# ATSAM4SP32A register map
Vendor: Atmel; File version: 0
CPU: CM4 r0p1, selectable endian, no MPU, no FPU, 0x4 interrupt priority bits, 0x0 interrupts
Registers are 32-bit, read-write, reset 0x0 unless marked. A register's access mark holds for its fields unless they carry their own. Offsets are from the block's base; [hi:lo] are bit positions; {n}, {i} and the like mark numbered series; 'fields as' and 'values as' point back to an identical list.

## CHIPID — Chip Identifier
Base 0x400E0740; register names take the prefix CHIPID_
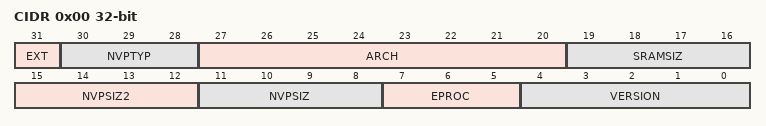
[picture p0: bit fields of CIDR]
0x00 CIDR ro reset not defined — Chip ID Register
  [31] EXT — Extension Flag
  [30:28] NVPTYP — Nonvolatile Program Memory Type
    0=ROM; 1=ROMLESS (ROMless or on-chip Flash); 2=FLASH (Embedded Flash Memory); 3=ROM_FLASH (ROM and Embedded Flash MemoryNVPSIZ is ROM size NVPSIZ2 is Flash size); 4=SRAM (SRAM emulating ROM)
  [27:20] ARCH — Architecture Identifier
    25=AT91SAM9xx Series; 41=AT91SAM9XExx Series; 52=AT91x34 Series; 55=CAP7 (CAP7 Series); 57=CAP9 (CAP9 Series); 59=CAP11 (CAP11 Series); 60=CM4P (CM4P Series); 64=AT91x40 Series; 66=AT91x42 Series; 85=AT91x55 Series; 96=AT91SAM7Axx Series; 97=AT91SAM7AQxx Series; 99=AT91x63 Series; 100=SAM4CxxC (SAM4CxC Series (100-pin version)); 101=SAM4MxxC Series (100-pin version); 112=AT91SAM7Sxx Series; 113=AT91SAM7XCxx Series; 114=AT91SAM7SExx Series; 115=AT91SAM7Lxx Series; 117=AT91SAM7Xxx Series; 118=AT91SAM7SLxx Series; 128=SAM3UxC Series (100-pin version); 129=SAM3UxE Series (144-pin version); 131=SAM3AxC Series (100-pin version); 132=SAM3XxC Series (100-pin version); 133=SAM3XxE Series (144-pin version); 134=SAM3XxG Series (208/217-pin version); 136=SAM3SxASeries (48-pin version); 136=SAM4SxA Series (48-pin version); 137=SAM3SxB Series (64-pin version); 137=SAM4SxB Series (64-pin version); 138=SAM3SxC Series (100-pin version); 138=SAM4SxC Series (100-pin version); 146=AT91x92 Series; 147=SAM3NxA Series (48-pin version); 148=SAM3NxB Series (64-pin version); 149=SAM3NxC Series (100-pin version); 153=SAM3SDxB Series (64-pin version); 154=SAM3SDxC Series (100-pin version); 165=SAM5A; 176=SAM4LxA Series (48-pin version); 177=SAM4LxB Series (64-pin version); 178=SAM4LxC Series (100-pin version); 240=AT75Cxx Series
  [19:16] SRAMSIZ — Internal SRAM Size
    0=48K (48 Kbytes); 1=192K (192 Kbytes); 2=2K (2 Kbytes); 3=6K (6 Kbytes); 4=24K (24 Kbytes); 5=4K (4 Kbytes); 6=80K (80 Kbytes); 7=160K (160 Kbytes); 8=8K (8 Kbytes); 9=16K (16 Kbytes); 10=32K (32 Kbytes); 11=64K (64 Kbytes); 12=128K (128 Kbytes); 13=256K (256 Kbytes); 14=96K (96 Kbytes); 15=512K (512 Kbytes)
  [15:12] NVPSIZ2 — Second Nonvolatile Program Memory Size
    0=NONE; 1=8K (8 Kbytes); 2=16K (16 Kbytes); 3=32K (32 Kbytes); 5=64K (64 Kbytes); 7=128K (128 Kbytes); 9=256K (256 Kbytes); 10=512K (512 Kbytes); 12=1024K (1024 Kbytes); 14=2048K (2048 Kbytes)
  [11:8] NVPSIZ — Nonvolatile Program Memory Size
    values as NVPSIZ2
  [7:5] EPROC — Embedded Processor
    1=ARM946ES; 2=ARM7TDMI; 3=CM3 (Cortex-M3); 4=ARM920T; 5=ARM926EJS; 6=CA5 (Cortex-A5); 7=CM4 (Cortex-M4)
  [4:0] VERSION — Version of the Device
0x04 EXID ro reset not defined — Chip ID Extension Register
  [31:0] EXID — Chip ID Extension

## EFC0 — Embedded Flash Controller 0
Base 0x400E0A00; register names take the prefix EFC0_
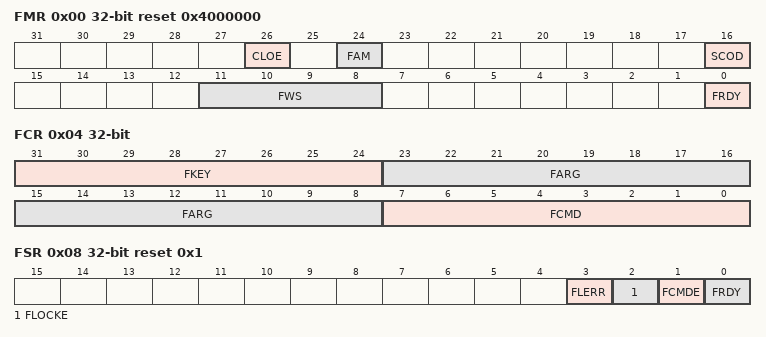
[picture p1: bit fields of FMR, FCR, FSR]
0x00 FMR reset 0x4000000 — EEFC Flash Mode Register
  [26] CLOE — Code Loops Optimization Enable
  [24] FAM — Flash Access Mode
  [16] SCOD — Sequential Code Optimization Disable
  [11:8] FWS — Flash Wait State
  [0] FRDY — Ready Interrupt Enable
0x04 FCR wo reset not defined — EEFC Flash Command Register
  [31:24] FKEY — Flash Writing Protection Key
    90=PASSWD (The 0x5A value enables the command defined by the bits of the register. If the field is written with a different value, the write is not performed and no action is started.)
  [23:8] FARG — Flash Command Argument
  [7:0] FCMD — Flash Command
    0=GETD (Get Flash Descriptor); 1=WP (Write page); 2=WPL (Write page and lock); 3=EWP (Erase page and write page); 4=EWPL (Erase page and write page then lock); 5=EA (Erase all); 7=EPA (Erase Pages); 8=SLB (Set Lock Bit); 9=CLB (Clear Lock Bit); 10=GLB (Get Lock Bit); 11=SGPB (Set GPNVM Bit); 12=CGPB (Clear GPNVM Bit); 13=GGPB (Get GPNVM Bit); 14=STUI (Start Read Unique Identifier); 15=SPUI (Stop Read Unique Identifier); 16=GCALB (Get CALIB Bit); 17=ES (Erase Sector); 18=WUS (Write User Signature); 19=EUS (Erase User Signature); 20=STUS (Start Read User Signature); 21=SPUS (Stop Read User Signature)
0x08 FSR ro reset 0x1 — EEFC Flash Status Register
  [3] FLERR — Flash Error Status
  [2] FLOCKE — Flash Lock Error Status
  [1] FCMDE — Flash Command Error Status
  [0] FRDY — Flash Ready Status
0x0C FRR ro — EEFC Flash Result Register
  [31:0] FVALUE — Flash Result Value

## EFC1 — Embedded Flash Controller 1
Base 0x400E0C00; register names take the prefix EFC1_
Registers as EFC0.

## RSTC — Reset Controller
Base 0x400E1400; register names take the prefix RSTC_
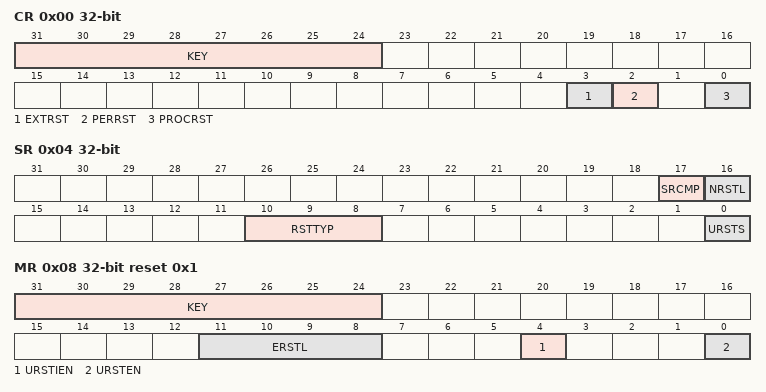
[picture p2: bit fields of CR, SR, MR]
0x00 CR wo reset not defined — Control Register
  [31:24] KEY — System Reset Key
  [3] EXTRST — External Reset
  [2] PERRST — Peripheral Reset
  [0] PROCRST — Processor Reset
0x04 SR ro — Status Register
  [17] SRCMP — Software Reset Command in Progress
  [16] NRSTL — NRST Pin Level
  [10:8] RSTTYP — Reset Type
  [0] URSTS — User Reset Status
0x08 MR reset 0x1 — Mode Register
  [31:24] KEY — Password
  [11:8] ERSTL — External Reset Length
  [4] URSTIEN — User Reset Interrupt Enable
  [0] URSTEN — User Reset Enable

## RTT — Real-time Timer
Base 0x400E1430; register names take the prefix RTT_
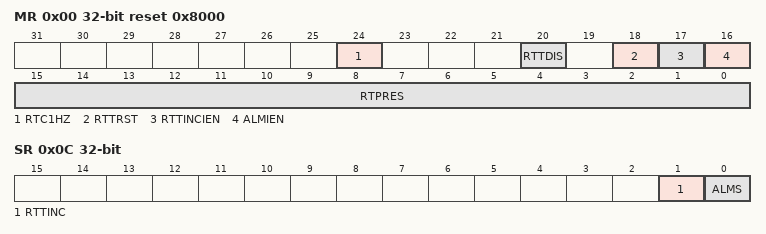
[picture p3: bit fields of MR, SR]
0x00 MR reset 0x8000 — Mode Register
  [24] RTC1HZ — Real-Time Clock 1Hz Clock Selection
  [20] RTTDIS — Real-time Timer Disable
  [18] RTTRST — Real-time Timer Restart
  [17] RTTINCIEN — Real-time Timer Increment Interrupt Enable
  [16] ALMIEN — Alarm Interrupt Enable
  [15:0] RTPRES — Real-time Timer Prescaler Value
0x04 AR reset 0xFFFFFFFF — Alarm Register
  [31:0] ALMV — Alarm Value
0x08 VR ro — Value Register
  [31:0] CRTV — Current Real-time Value
0x0C SR ro — Status Register
  [1] RTTINC — Real-time Timer Increment
  [0] ALMS — Real-time Alarm Status

## WDT — Watchdog Timer
Base 0x400E1450; register names take the prefix WDT_
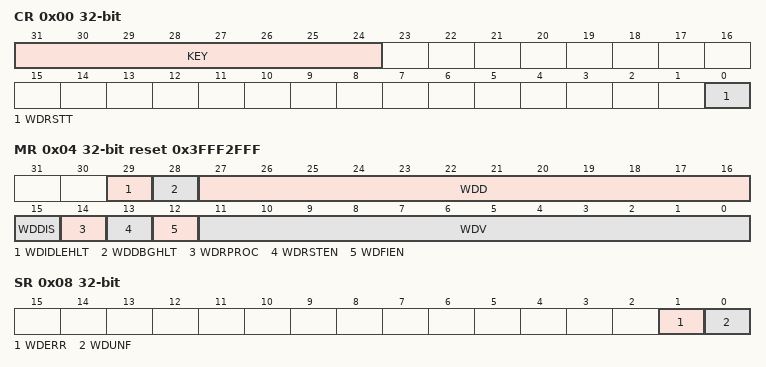
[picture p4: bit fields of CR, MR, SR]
0x00 CR wo reset not defined — Control Register
  [31:24] KEY — Password
  [0] WDRSTT — Watchdog Restart
0x04 MR reset 0x3FFF2FFF — Mode Register
  [29] WDIDLEHLT — Watchdog Idle Halt
  [28] WDDBGHLT — Watchdog Debug Halt
  [27:16] WDD — Watchdog Delta Value
  [15] WDDIS — Watchdog Disable
  [14] WDRPROC — Watchdog Reset Processor
  [13] WDRSTEN — Watchdog Reset Enable
  [12] WDFIEN — Watchdog Fault Interrupt Enable
  [11:0] WDV — Watchdog Counter Value
0x08 SR ro — Status Register
  [1] WDERR — Watchdog Error
  [0] WDUNF — Watchdog Underflow

## GPBR — General Purpose Backup Register
Base 0x400E1490; register names take the prefix GPBR_
{0x0+4i} GPBR[{i}] reset not defined (i=0..7) — General Purpose Backup Register
  [31:0] GPBR_VALUE — Value of GPBR x
